# AC7802x register map
Vendor: AutoChips; Series: AC78; File version: 1.0
CPU: CM0PLUS r0p1, little endian, no MPU, no FPU, VTOR, 2 interrupt priority bits
Registers are 32-bit, read-write, reset 0x0 unless marked. A register's access mark holds for its fields unless they carry their own. Offsets are from the block's base; [hi:lo] are bit positions; {n}, {i} and the like mark numbered series.

## CKGEN — Clock Generator
Base 0x40000000
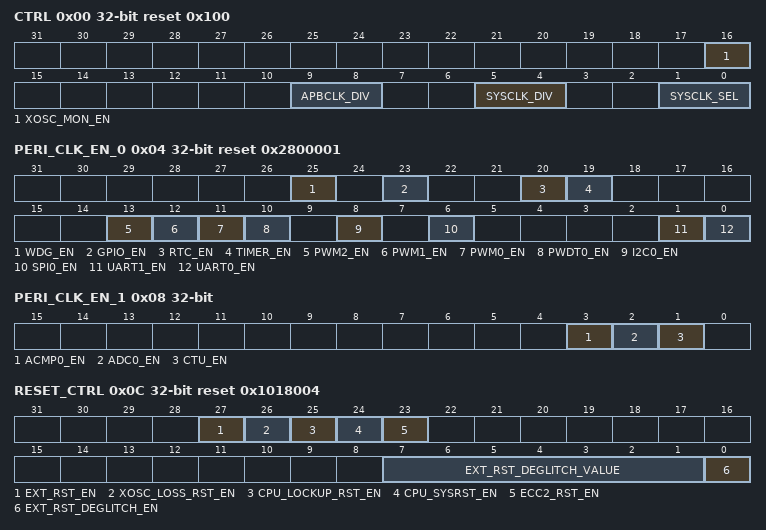
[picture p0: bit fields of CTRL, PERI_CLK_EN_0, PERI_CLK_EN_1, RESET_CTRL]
0x00 CTRL reset 0x100 — CKGEN Control Register
  [16] XOSC_MON_EN — XOSC Monitor Function Enable
    0=Monitor Function Disable; 1=Monitor Function Enable
  [9:8] APBCLK_DIV — APB Clcok Divider
    {v}=APB Clock Divided By {v+1} (v=0..3)
  [5:4] SYSCLK_DIV — System Clock Divider
    0=System Clock Divided By 1; 1=System Clock Divided By 2; 2=System Clock Divided By 4; 3=System Clock Divided By 16
  [1:0] SYSCLK_SEL — system clock select
    0=Internal RC; 2=External XOSC
0x04 PERI_CLK_EN_0 reset 0x2800001 — Periph Clock Enable Control 0
  [all] fields
    0=Clock Disable; 1=Clock Enable
  [25] WDG_EN — WDG Clock Enable
  [23] GPIO_EN — GPIO Clock Enable
  [20] RTC_EN — RTC Clock Enable
  [19] TIMER_EN — TIMER Clock Enable
  [13] PWM2_EN — PWM2 Clock Enable
  [12] PWM1_EN — PWM1 Clock Enable
  [11] PWM0_EN — PWM0 Clock Enable
  [10] PWDT0_EN — PWDT0 Clock Enable
  [8] I2C0_EN — I2C0 Clock Enable
  [6] SPI0_EN — SPI0 Clock Enable
  [1] UART1_EN — UART1 Clock Enable
  [0] UART0_EN — UART0 Clock Enable
0x08 PERI_CLK_EN_1 — Periph Clock Enable Control 1
  [all] fields
    0=Clock Disable; 1=Clock Enable
  [3] ACMP0_EN — ACMP0 Clock Enable
  [2] ADC0_EN — ADC0 Clock Enable
  [1] CTU_EN — CTU APB Clock Enable
0x0C RESET_CTRL reset 0x1018004 — MCU Reset Control
  [27] EXT_RST_EN — External Reset Enable
    0=Disable; 1=Enable
  [26] XOSC_LOSS_RST_EN — XOSC Loss Reset Enable
    0=Disable; 1=Enable
  [25] CPU_LOCKUP_RST_EN — CPU Lockup Reset Enable
    0=Disable; 1=Enable
  [24] CPU_SYSRST_EN — CPU System Reset Enable
    0=Disable; 1=Enable
  [23] ECC2_RST_EN — ECC2 Error Reset Enable
    0=Disable; 1=Enable
  [7:1] EXT_RST_DEGLITCH_VALUE — Deglitch Value Set
  [0] EXT_RST_DEGLITCH_EN — EXT Reset Deglitch Enable
    0=Deglitch Disable; 1=Deglitch Enable
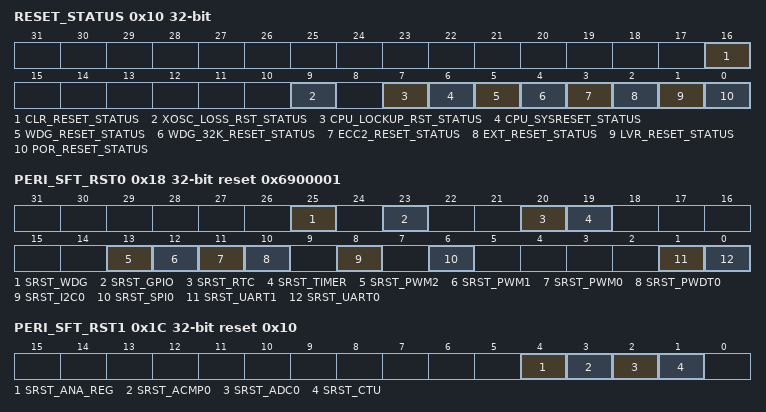
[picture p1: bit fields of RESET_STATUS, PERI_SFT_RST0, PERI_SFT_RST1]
0x10 RESET_STATUS — MCU Reset Status
  [16] CLR_RESET_STATUS — clear All Reset Status
    0=reset update; 1=clear all reset status
  [9] XOSC_LOSS_RST_STATUS ro — XOSC Loss Reset Flag
    0=Reset Not Happen; 1=Reset Happen
  [7] CPU_LOCKUP_RST_STATUS ro — CPU Lockup Reset Flag
    0=Reset Not Happen; 1=Reset Happen
  [6] CPU_SYSRESET_STATUS ro — CPU Sysreset Reset Flag
    0=Reset Not Happen; 1=Reset Happen
  [5] WDG_RESET_STATUS ro — WDG Reset Flag
    0=Reset Not Happen; 1=Reset Happen
  [4] WDG_32K_RESET_STATUS ro — WDG 32K Reset Flag
    0=Reset Not Happen; 1=Reset Happen
  [3] ECC2_RESET_STATUS ro — ECC 2bit Error Reset Flag
    0=Reset Not Happen; 1=Reset Happen
  [2] EXT_RESET_STATUS ro — EXT Reset Flag
    0=Reset Not Happen; 1=Reset Happen
  [1] LVR_RESET_STATUS ro — LVR Reset Flag
    0=Reset Not Happen; 1=Reset Happen
  [0] POR_RESET_STATUS ro — POR Reset Flag
    0=Reset Not Happen; 1=Reset Happen
0x18 PERI_SFT_RST0 reset 0x6900001 — Periph Software Reset Control 0
  [all] fields
    0=Reset Active; 1=Reset Inactive
  [25] SRST_WDG — WDG Software Reset
  [23] SRST_GPIO — GPIO Software Reset
  [20] SRST_RTC — RTC Software Reset
  [19] SRST_TIMER — TIMER Software Reset
  [13] SRST_PWM2 — PWM2 Software Reset
  [12] SRST_PWM1 — PWM1 Software Reset
  [11] SRST_PWM0 — PWM0 Software Reset
  [10] SRST_PWDT0 — PWDT0 Software Reset
  [8] SRST_I2C0 — I2C0 Software Reset
  [6] SRST_SPI0 — SPI0 Software Reset
  [1] SRST_UART1 — UART1 Software Reset
  [0] SRST_UART0 — UART0 Software Reset
0x1C PERI_SFT_RST1 reset 0x10 — Periph Software Reset Control 1
  [all] fields
    0=Reset Active; 1=Reset Inactive
  [4] SRST_ANA_REG — Analog Register Software Reset
  [3] SRST_ACMP0 — ACMP0 Software Reset
  [2] SRST_ADC0 — ADC0 Software Reset
  [1] SRST_CTU — CTU Software Reset
